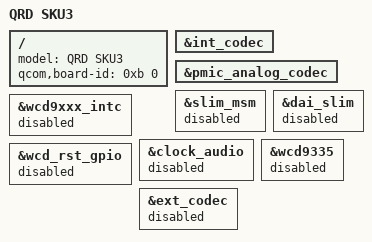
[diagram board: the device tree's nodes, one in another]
/*
 * Copyright (c) 2018, 2020 The Linux Foundation. All rights reserved.
 *
 * This program is free software; you can redistribute it and/or modify
 * it under the terms of the GNU General Public License version 2 and
 * only version 2 as published by the Free Software Foundation.
 *
 * This program is distributed in the hope that it will be useful,
 * but WITHOUT ANY WARRANTY; without even the implied warranty of
 * MERCHANTABILITY or FITNESS FOR A PARTICULAR PURPOSE.  See the
 * GNU General Public License for more details.
 */

/dts-v1/;
/plugin/;

#include "msm8953-qrd-sku3.dtsi"

/ {
	model = "QRD SKU3";
	qcom,board-id = <0xb 0>;
};

&int_codec {
	status = "okay";
};

&pmic_analog_codec {
	status = "okay";
};

&slim_msm {
	status = "disabled";
};

&dai_slim {
	status = "disabled";
};

&wcd9xxx_intc {
	status = "disabled";
};

&clock_audio {
	status = "disabled";
};

&wcd9335 {
	status = "disabled";
};

&wcd_rst_gpio {
	status = "disabled";
};

&ext_codec {
	status = "disabled";
};
